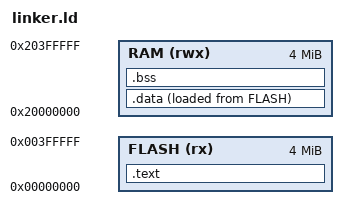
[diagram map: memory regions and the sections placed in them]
MEMORY
{
    FLASH (rx)  : ORIGIN = 0x00000000, LENGTH = 4M
    RAM   (rwx) : ORIGIN = 0x20000000, LENGTH = 4M
}

SECTIONS
{
    .text :
    {
        KEEP(*(.isr_vector))
        *(.text*)
        *(.rodata*)
    } > FLASH

    .data :
    {
        _sidata = LOADADDR(.data);
        _sdata = .;
        *(.data*)
        _edata = .;
    } > RAM AT > FLASH

    .bss :
    {
        _sbss = .;
        __bss_start__ = .;
        *(.bss*)
        *(COMMON)
        _ebss = .;
        __bss_end__ = .;
    } > RAM

    end = .;
    _end = .;

    _estack = ORIGIN(RAM) + LENGTH(RAM);

    /DISCARD/ :
    {
        *(.ARM.exidx*)
        *(.ARM.attributes*)
    }
}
